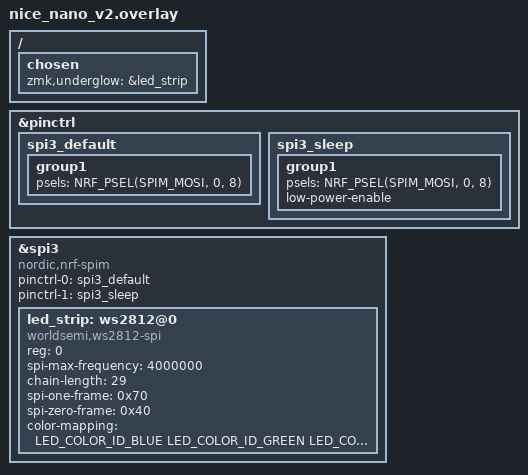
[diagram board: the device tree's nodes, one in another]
#include <dt-bindings/led/led.h>

&pinctrl {
    spi3_default: spi3_default {
        group1 {
            psels = <NRF_PSEL(SPIM_MOSI, 0, 8)>;
        };
    };

    spi3_sleep: spi3_sleep {
        group1 {
            psels = <NRF_PSEL(SPIM_MOSI, 0, 8)>;
            low-power-enable;
        };
    };
};

&spi3 {
    compatible = "nordic,nrf-spim";
    status = "okay";

    pinctrl-0 = <&spi3_default>;
    pinctrl-1 = <&spi3_sleep>;
    pinctrl-names = "default", "sleep";

    led_strip: ws2812@0 {
        compatible = "worldsemi,ws2812-spi";

        /* SPI */
        reg = <0>; /* ignored, but necessary for SPI bindings */
        spi-max-frequency = <4000000>;

        /* WS2812/SK6812 */
        chain-length = <29>; /* 29 LEDs per side */
        spi-one-frame = <0x70>;
        spi-zero-frame = <0x40>;

        /* SK6812 MINI E color order - testing BGR */
        /* Try these if colors are wrong:
         * RGB: <LED_COLOR_ID_RED LED_COLOR_ID_GREEN LED_COLOR_ID_BLUE>
         * GRB: <LED_COLOR_ID_GREEN LED_COLOR_ID_RED LED_COLOR_ID_BLUE>
         * BGR: <LED_COLOR_ID_BLUE LED_COLOR_ID_GREEN LED_COLOR_ID_RED>
         * BRG: <LED_COLOR_ID_BLUE LED_COLOR_ID_RED LED_COLOR_ID_GREEN>
         * GBR: <LED_COLOR_ID_GREEN LED_COLOR_ID_BLUE LED_COLOR_ID_RED>
         * RBG: <LED_COLOR_ID_RED LED_COLOR_ID_BLUE LED_COLOR_ID_GREEN>
         */
        color-mapping = <LED_COLOR_ID_BLUE LED_COLOR_ID_GREEN LED_COLOR_ID_RED>;
    };
};

/ {
    chosen {
        zmk,underglow = &led_strip;
    };
};
